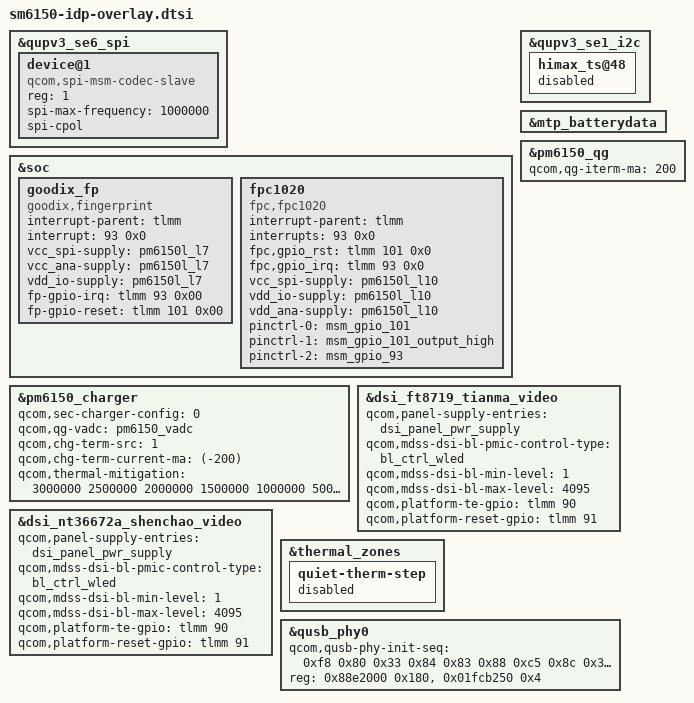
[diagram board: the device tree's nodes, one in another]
/* SPDX-License-Identifier: GPL-2.0 */

#include "sm6150-novatek-i2c_f7b.dtsi"
#include "sm6150-ft8719-i2c_f7b.dtsi"

&qupv3_se6_spi {
	status = "ok";
	device@1 {
		compatible = "qcom,spi-msm-codec-slave";
		#address-cells = <1>;
		#size-cells = <1>;
		reg = <1>; /* Chip select 0 */
		spi-max-frequency = <1000000>;
		spi-cpol;
	};
};

&soc {
	goodix_fp {
	compatible = "goodix,fingerprint";
	interrupt-parent = <&tlmm>;
	interrupt = <93 0x0>;
	vcc_spi-supply = <&pm6150l_l7>;
	vcc_ana-supply = <&pm6150l_l7>;
	vdd_io-supply = <&pm6150l_l7>;
	fp-gpio-irq = <&tlmm 93 0x00>;
	fp-gpio-reset = <&tlmm 101 0x00>;
	status = "okay";
	};

	fpc1020 {
		status = "ok";
		compatible = "fpc,fpc1020";
		interrupt-parent = <&tlmm>;
		interrupts = <93 0x0>;
		fpc,gpio_rst    = <&tlmm 101 0x0>;
		fpc,gpio_irq    = <&tlmm 93 0x0>;
		vcc_spi-supply  = <&pm6150l_l10>;
		vdd_io-supply   = <&pm6150l_l10>;
		vdd_ana-supply  = <&pm6150l_l10>;

		pinctrl-names = "fpc1020_reset_reset",
			"fpc1020_reset_active",
			"fpc1020_irq_active";

		pinctrl-0 = <&msm_gpio_101>;
		pinctrl-1 = <&msm_gpio_101_output_high>;
		pinctrl-2 = <&msm_gpio_93>;
	};
};

&qupv3_se1_i2c {
	himax_ts@48 {
		status = "disabled";
	};
};

&mtp_batterydata {
	#include "LC_M6300_ATL4000mAh_3633204_FG.dtsi"
	#include "LC_M6300_Sunwoda4000mAh_3632066_FG.dtsi"
};

&pm6150_qg {
	/delete-property/ qcom,qg-iterm-ma ;
	qcom,qg-iterm-ma = <200>;
};

&pm6150_charger {
	/delete-property/ qcom,thermal-mitigation;
	qcom,sec-charger-config = <0>;
	qcom,qg-vadc = <&pm6150_vadc>;
	qcom,chg-term-src = <1>;
	qcom,chg-term-current-ma = <(-200)>;
	qcom,thermal-mitigation = <3000000
			2500000 2000000 1500000 1000000 500000>;
};

&dsi_ft8719_tianma_video {
	qcom,panel-supply-entries = <&dsi_panel_pwr_supply>;
	qcom,mdss-dsi-bl-pmic-control-type = "bl_ctrl_wled";
	qcom,mdss-dsi-bl-min-level = <1>;
	qcom,mdss-dsi-bl-max-level = <4095>;
	qcom,platform-te-gpio = <&tlmm 90 0>;
	qcom,platform-reset-gpio = <&tlmm 91 0>;
};

&dsi_nt36672a_shenchao_video {
	qcom,panel-supply-entries = <&dsi_panel_pwr_supply>;
	qcom,mdss-dsi-bl-pmic-control-type = "bl_ctrl_wled";
	qcom,mdss-dsi-bl-min-level = <1>;
	qcom,mdss-dsi-bl-max-level = <4095>;
	qcom,platform-te-gpio = <&tlmm 90 0>;
	qcom,platform-reset-gpio = <&tlmm 91 0>;
};

&thermal_zones {
	quiet-therm-step {
		status = "disabled";
	};
};

&qusb_phy0 {
	/delete-property/ qcom,qusb-phy-init-seq;
	/delete-property/ reg;
	/delete-property/ reg-names;
	qcom,qusb-phy-init-seq = <0xf8 0x80
					0x33 0x84
					0x83 0x88
					0xc5 0x8c
					0x30 0x08
					0x79 0x0c
					0x21 0x10
					0x14 0x9c
					0x9f 0x1c
					0x00 0x18>;
	reg = <0x88e2000 0x180>,
		<0x01fcb250 0x4>;
	reg-names = "qusb_phy_base",
		"tcsr_clamp_dig_n_1p8";
};
